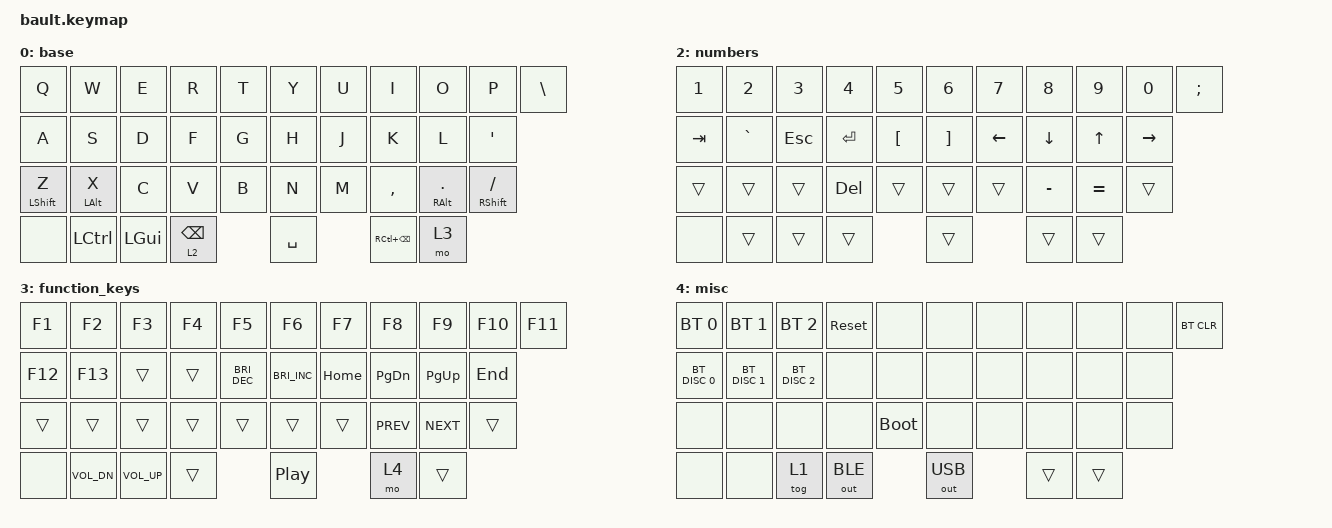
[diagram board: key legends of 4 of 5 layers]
#include <behaviors.dtsi>
#include <dt-bindings/zmk/bt.h>
#include <dt-bindings/zmk/keys.h>
#include <dt-bindings/zmk/outputs.h>

&lt {
    flavor = "hold-preferred";
    tapping-term-ms = <150>;
};

/ {
    behaviors {
        hm: homerow_mods {
            compatible = "zmk,behavior-hold-tap";
            display-name = "Homerow Mods";
            bindings = <&kp>, <&kp>;

            #binding-cells = <2>;
            tapping-term-ms = <200>;
            quick-tap-ms = <180>;
            require-prior-idle-ms = <80>;
            flavor = "tap-preferred";
        };
    };

    combos {
        compatible = "zmk,combos";

        Dash {
            bindings = <&kp MINUS>;
            key-positions = <29 28>;
            layers = <0 2>;
            require-prior-idle-ms = <80>;
        };

        Underscore {
            bindings = <&kp UNDERSCORE>;
            key-positions = <28 29 30>;
            require-prior-idle-ms = <80>;
            layers = <0 2>;
        };

        Plus {
            bindings = <&kp KP_PLUS>;
            key-positions = <28 30>;
            require-prior-idle-ms = <80>;
            layers = <0 2>;
        };

        Equals {
            bindings = <&kp KP_EQUAL>;
            key-positions = <29 30>;
            require-prior-idle-ms = <80>;
            layers = <0 2>;
        };

        Semicolon {
            bindings = <&kp SEMICOLON>;
            key-positions = <20 28>;
            require-prior-idle-ms = <80>;
            layers = <0 2>;
        };

        Colon {
            bindings = <&kp COLON>;
            key-positions = <20 29>;
            require-prior-idle-ms = <80>;
            layers = <0 2>;
        };

        Bootloader {
            bindings = <&bootloader>;
            key-positions = <21 25>;
            require-prior-idle-ms = <2000>;
            layers = <4>;
        };

        DelBT {
            bindings = <&bt BT_CLR_ALL>;
            key-positions = <10 9>;
            require-prior-idle-ms = <300>;
            layers = <4>;
        };
    };

    keymap {
        compatible = "zmk,keymap";

        base {
            bindings = <
&kp Q             &kp W             &kp E         &kp R            &kp T  &kp Y      &kp U  &kp I              &kp O                 &kp P                  &kp BACKSLASH
&kp A             &kp S             &kp D         &kp F            &kp G  &kp H      &kp J  &kp K              &kp L                 &kp SINGLE_QUOTE
&mt LEFT_SHIFT Z  &hm LEFT_ALT X    &kp C         &kp V            &kp B  &kp N      &kp M  &kp COMMA          &hm RIGHT_ALT PERIOD  &mt RIGHT_SHIFT SLASH
&none             &kp LEFT_CONTROL  &kp LEFT_GUI  &lt 2 BACKSPACE         &kp SPACE         &kp RC(BACKSPACE)  &mo 3
            >;
        };

        Mac {
            bindings = <
&trans  &trans  &trans  &trans  &trans  &trans  &trans  &trans             &trans  &trans  &trans
&trans  &trans  &trans  &trans  &trans  &trans  &trans  &trans             &trans  &trans
&trans  &trans  &trans  &trans  &trans  &trans  &trans  &trans             &trans  &trans
&trans  &trans  &trans  &trans          &trans          &kp RA(BACKSPACE)  &trans  &trans
            >;
        };

        numbers {
            bindings = <
&kp N1   &kp N2     &kp N3      &kp N4      &kp N5            &kp N6             &kp N7          &kp N8          &kp N9        &kp N0           &kp SEMICOLON
&kp TAB  &kp GRAVE  &kp ESCAPE  &kp RETURN  &kp LEFT_BRACKET  &kp RIGHT_BRACKET  &kp LEFT_ARROW  &kp DOWN_ARROW  &kp UP_ARROW  &kp RIGHT_ARROW
&trans   &trans     &trans      &kp DELETE  &trans            &trans             &trans          &kp MINUS       &kp EQUAL     &trans
&none    &trans     &trans      &trans                        &trans                             &trans          &trans
            >;
        };

        function_keys {
            bindings = <
&kp F1   &kp F2        &kp F3        &kp F4  &kp F5                &kp F6                &kp F7    &kp F8         &kp F9      &kp F10  &kp F11
&kp F12  &kp F13       &trans        &trans  &kp C_BRIGHTNESS_DEC  &kp C_BRIGHTNESS_INC  &kp HOME  &kp PAGE_DOWN  &kp PG_UP   &kp END
&trans   &trans        &trans        &trans  &trans                &trans                &trans    &kp C_PREV     &kp C_NEXT  &trans
&none    &kp C_VOL_DN  &kp C_VOL_UP  &trans                        &kp C_PLAY_PAUSE                &mo 4          &trans
            >;
        };

        misc {
            bindings = <
&bt BT_SEL 0   &bt BT_SEL 1   &bt BT_SEL 2   &sys_reset    &none        &none         &none  &none   &none   &none  &bt BT_CLR
&bt BT_DISC 0  &bt BT_DISC 1  &bt BT_DISC 2  &none         &none        &none         &none  &none   &none   &none
&none          &none          &none          &none         &bootloader  &none         &none  &none   &none   &none
&none          &none          &tog 1         &out OUT_BLE               &out OUT_USB         &trans  &trans
            >;
        };
    };
};
